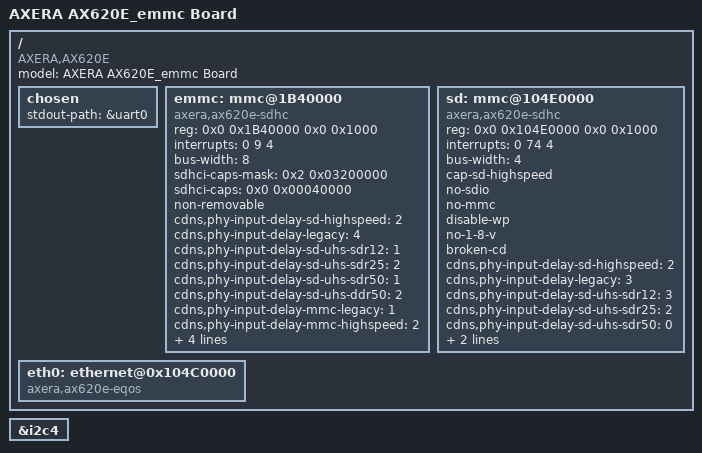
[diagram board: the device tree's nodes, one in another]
/*
 * (C) Copyright 2020 AXERA Co., Ltd
 *
 * SPDX-License-Identifier:     GPL-2.0+
 */

/dts-v1/;
#include <dt-bindings/pwm/pwm.h>
#include "ax620e.dtsi"

/ {
	model = "AXERA AX620E_emmc Board";
	compatible = "AXERA,AX620E", "axera,ax620e";

	chosen {
		stdout-path = &uart0;
	};

	emmc: mmc@1B40000 {
		compatible = "axera,ax620e-sdhc";
		reg = <0x0 0x1B40000 0x0 0x1000>;
		interrupts = <0 9 4>;
		bus-width = <8>;
		sdhci-caps-mask = <0x2 0x03200000>;
		sdhci-caps = <0x0 0x00040000>;
		non-removable;
		cdns,phy-input-delay-sd-highspeed = <2>;
		cdns,phy-input-delay-legacy = <4>;
		cdns,phy-input-delay-sd-uhs-sdr12 = <1>;
		cdns,phy-input-delay-sd-uhs-sdr25 = <2>;
		cdns,phy-input-delay-sd-uhs-sdr50 = <1>;
		cdns,phy-input-delay-sd-uhs-ddr50 = <2>;
		cdns,phy-input-delay-mmc-legacy = <1>;
		cdns,phy-input-delay-mmc-highspeed = <2>;
		cdns,phy-input-delay-mmc-ddr = <2>;
		cdns,phy-dll-delay-sdclk = <0>;
		cdns,phy-dll-delay-sdclk-hsmmc = <23>;
		cdns,phy-dll-delay-strobe = <18>;
		status = "okay";
	};

	sd: mmc@104E0000 {
		compatible = "axera,ax620e-sdhc";
		reg = <0x0 0x104E0000 0x0 0x1000>;
		interrupts = <0 74 4>;

		bus-width = <4>;
		cap-sd-highspeed;
		/*sd-uhs-sdr12;
		sd-uhs-sdr25;
		sd-uhs-sdr50;*/
		no-sdio;
		no-mmc;
		disable-wp;
		no-1-8-v;
		broken-cd;

		cdns,phy-input-delay-sd-highspeed = <2>;
		cdns,phy-input-delay-legacy = <3>;
		cdns,phy-input-delay-sd-uhs-sdr12 = <3>;
		cdns,phy-input-delay-sd-uhs-sdr25 = <2>;
		cdns,phy-input-delay-sd-uhs-sdr50 = <0>;
		cdns,phy-input-delay-sd-uhs-ddr50 = <0>;
		cdns,phy-dll-delay-sdclk = <0>;

		status = "okay";
	};

	eth0: ethernet@0x104C0000{
		compatible = "axera,ax620e-eqos";
		status = "okay";
	};
};
&i2c4 {
	status = "okay";
};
